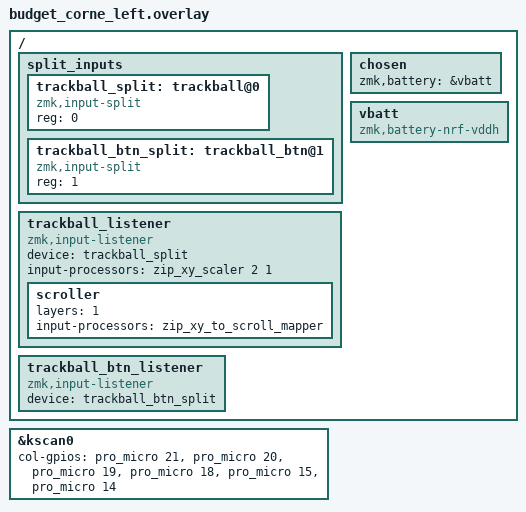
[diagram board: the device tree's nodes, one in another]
#include "budget_corne.dtsi"
#include <input/processors.dtsi>

/ {
	split_inputs {
		#address-cells = <1>;
		#size-cells = <0>;

		trackball_split: trackball@0 {
			compatible = "zmk,input-split";
			reg = <0>;
		};

		trackball_btn_split: trackball_btn@1 {
			compatible = "zmk,input-split";
			reg = <1>;
		};
	};

	trackball_listener {
		compatible = "zmk,input-listener";
		device = <&trackball_split>;
		input-processors = <&zip_xy_scaler 2 1>;

		scroller {
			layers = <1>;
			input-processors = <&zip_xy_to_scroll_mapper>;
		};
	};

	trackball_btn_listener {
		compatible = "zmk,input-listener";
		device = <&trackball_btn_split>;
	};
};

&kscan0 {
	col-gpios
		= <&pro_micro 21 GPIO_ACTIVE_HIGH>
		, <&pro_micro 20 GPIO_ACTIVE_HIGH>
		, <&pro_micro 19 GPIO_ACTIVE_HIGH>
		, <&pro_micro 18 GPIO_ACTIVE_HIGH>
		, <&pro_micro 15 GPIO_ACTIVE_HIGH>
		, <&pro_micro 14 GPIO_ACTIVE_HIGH>
		;
};

/ {
	chosen {
		zmk,battery = &vbatt;
	};

	vbatt: vbatt {
		compatible = "zmk,battery-nrf-vddh";
	};
};
